# PIC32CX5109BZ31032 register map
Vendor: Microchip Technology; Series: PIC32CXBZ31; File version: 0
CPU: CM4 r0p1, little endian, MPU, FPU, 3 interrupt priority bits, 43 interrupts
Registers are 32-bit, read-write, reset 0x0 unless marked. A register's access mark holds for its fields unless they carry their own. Offsets are from the block's base; [hi:lo] are bit positions.

## ROT — Secure Root of Trust Macro
Base 0x44002C00
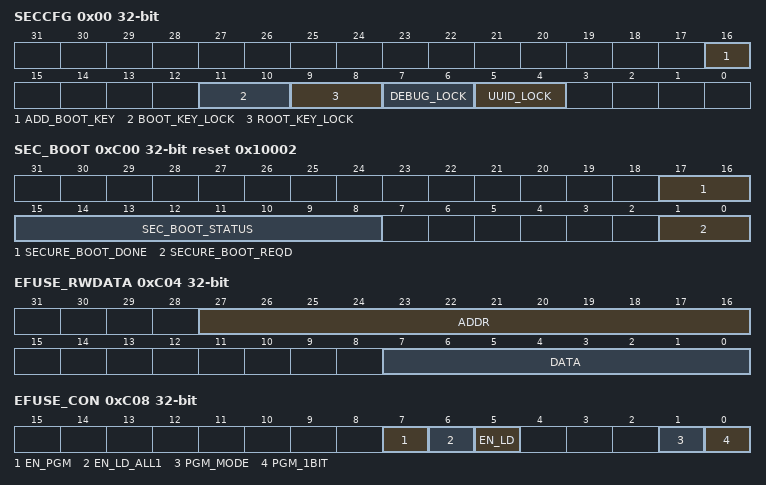
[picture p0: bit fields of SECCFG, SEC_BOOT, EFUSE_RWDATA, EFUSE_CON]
0x00 SECCFG — Secure Configuration HOLDING REGISTER1,2
  [16] ADD_BOOT_KEY — Additional boot Key bit
  [11:10] BOOT_KEY_LOCK — Lock bits for Secure Boot/OTA Key
    0=BOOT_KEY_NOT_LCK_0 (Secure boot key is not locked); 1=BOOT_KEY_LCK_1 (Secure boot key is locked and cannot be programmed); 2=BOOT_KEY_LCK_2 (Secure boot key is locked and cannot be programmed); 3=BOOT_KEY_LCK_3 (Secure boot key is locked and cannot be programmed)
  [9:8] ROOT_KEY_LOCK — Lock bits for storage root Key
    0=ROOT_KEY_NOT_LCK_0 (Storage root key is not locked); 1=ROOT_KEY_LCK_1 (Storage root key is locked and cannot be programmed); 2=ROOT_KEY_LCK_2 (Storage root key is locked and cannot be programmed); 3=ROOT_KEY_LCK_3 (Storage root key is locked and cannot be programmed)
  [7:6] DEBUG_LOCK — Lock bits for debug/programming
    0=DEBUG_NOT_LCK_0 (Debug is not locked); 1=DEBUG_LCK_1 (Debug is locked); 2=DEBUG_LCK_2 (Debug is locked); 3=DEBUG_LCK_3 (Debug is locked)
  [5:4] UUID_LOCK — Programming lock bits for Unique ID fuses
    0=UUID_NOT_LCK_0 (Unique ID is not locked); 1=UUID_LCK_1 (Unique ID is locked and cannot be programmed); 2=UUID_LCK_2 (Unique ID is locked and cannot be programmed); 3=UUID_LCK_3 (Unique ID is locked and cannot be programmed)
0xC00 SEC_BOOT reset 0x10002 — Secure Boot Register
  [17:16] SECURE_BOOT_DONE — Bits to indicate that secure boot is done
    0=SEC_BOOT_DONE_0 (S ecure boot is done); 1=SEC_BOOT_NOT_DONE_1 (S ecure boot is not done); 2=SEC_BOOT_NOT_DONE_2 (S ecure boot is not done); 3=SEC_BOOT_DONE_3 (S ecure boot is done)
  [15:8] SEC_BOOT_STATUS — Bits to indicate that secure boot status
  [1:0] SECURE_BOOT_REQD — Bits to indicate that secure boot is required on the next device reset.
    0=SEC_BOOT_REQD_0 (Secure boot code authentication is required); 1=SEC_BOOT_NOT_REQD_1 (Secure boot code authentication is NOT required); 2=SEC_BOOT_NOT_REQD_2 (Secure boot code authentication is NOT required); 3=SEC_BOOT_REQD_3 (Secure boot code authentication is required)
0xC04 EFUSE_RWDATA
  [27:16] ADDR — eFuse Program/Read Address
  [7:0] DATA — eFuse Program (Write) Data
0xC08 EFUSE_CON — Efuse Configuration Register2
  [7] EN_PGM — eFuse Programming Start bit
    0=EN_PGM_COMPLETED (EFuse Programming operation has completed); 1=EN_PGM_START (Start eFuse Programming operation)
  [6] EN_LD_ALL1 — eFuse Panel Read Start bit for loading into the holding registers
    0=ENLD_ALL1_READ_COMPLETED (EFuse Read operation has completed); 1=ENLD_ALL1_READ_START (Start eFuse Read operation for entire eFuse panel)
  [5] EN_LD — eFuse Word Read Start bit for loading the fuse byte pointed by ADDR field into the holding register
    0=ENLD_READ_COMPLETED (EFuse Read operation has completed); 1=ENLD_READ_START (Start eFuse Read operation for specified eFuse word as addressed in EFUSE_RWDATA register)
  [1] PGM_MODE — eFuse Programming Mode Enable bit
    0=PGM_MODE_DISABLED (EFuse Programming disabled); 1=PGM_MODE_ENABLED (EFuse Programming enabled)
  [0] PGM_1BIT — eFuse CTRL to program 1 bit at a time. Valid only when EN_PGM is set
    0=EFUSE_RW_15_0 (EFuse controller will program EFUSE_RWDATA.DATA[15:0] to the address in EFUSE_RWDATA.ADDR[11:3]); 1=EFUSE_RW_0 (EFuse controller will program EFUSE_RWDATA.DATA[0] to the address in EFUSE_RWDATA.ADDR[11:0])

## SysTick — System timer
Base 0xE000E010
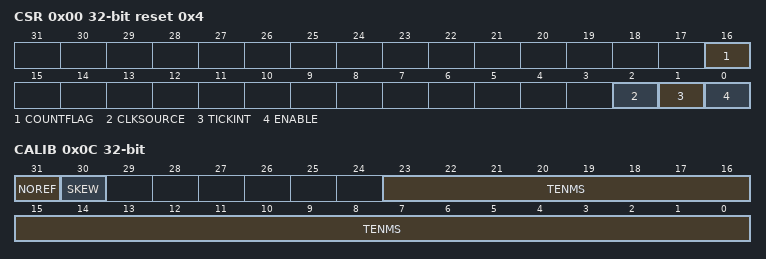
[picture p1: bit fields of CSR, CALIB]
0x00 CSR reset 0x4 — SysTick Control and Status Register
  [16] COUNTFLAG — Timer counted to 0 since last read of register
  [2] CLKSOURCE — Clock Source 0=external, 1=processor
    0=External clock; 1=Processor clock
  [1] TICKINT — SysTick Exception Request Enable
    0=Counting down to 0 does not assert the SysTick exception request; 1=Counting down to 0 asserts the SysTick exception request
  [0] ENABLE — SysTick Counter Enable
    0=Counter disabled; 1=Counter enabled
0x04 RVR — SysTick Reload Value Register
  [23:0] RELOAD — Value to load into the SysTick Current Value Register when the counter reaches 0
0x08 CVR — SysTick Current Value Register
  [23:0] CURRENT — Current value at the time the register is accessed
0x0C CALIB ro — SysTick Calibration Value Register
  [31] NOREF — No Separate Reference Clock
    0=The reference clock is provided; 1=The reference clock is not provided
  [30] SKEW — TENMS is rounded from non-integer ratio
    0=10ms calibration value is exact; 1=10ms calibration value is inexact, because of the clock frequency
  [23:0] TENMS — Reload value to use for 10ms timing

## TPI — Trace Port Interface Register
Base 0xE0040000
0x00 SSPSR ro — Supported Parallel Port Size Register
0x04 CSPSR — Current Parallel Port Size Register
0x10 ACPR — Asynchronous Clock Prescaler Register
  [12:0] PRESCALER
0xF0 SPPR — Selected Pin Protocol Register
  [1:0] TXMODE
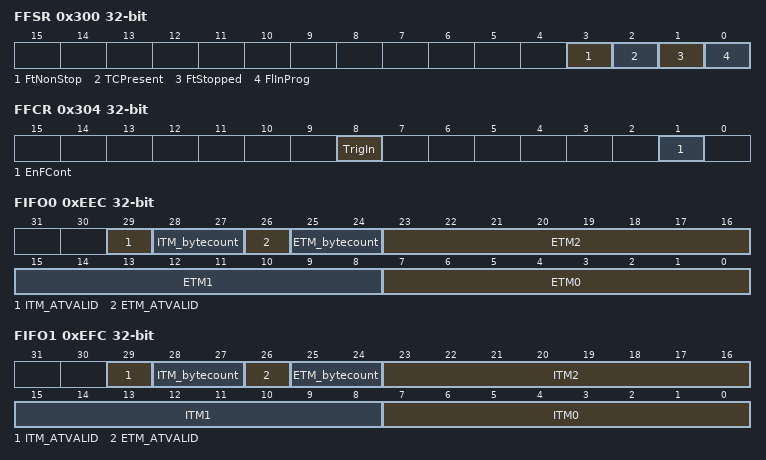
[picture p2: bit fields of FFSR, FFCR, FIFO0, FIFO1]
0x300 FFSR ro — Formatter and Flush Status Register
  [3] FtNonStop, [2] TCPresent, [1] FtStopped, [0] FlInProg
0x304 FFCR — Formatter and Flush Control Register
  [8] TrigIn, [1] EnFCont
0x308 FSCR ro — Formatter Synchronization Counter Register
0xEE8 TRIGGER ro
  [0] TRIGGER
0xEEC FIFO0 ro — Integration ETM Data
  [29] ITM_ATVALID, [28:27] ITM_bytecount, [26] ETM_ATVALID, [25:24] ETM_bytecount, [23:16] ETM2, [15:8] ETM1, [7:0] ETM0
0xEF0 ITATBCTR2 ro
  [0] ATREADY
0xEF8 ITATBCTR0 ro
  [0] ATREADY
0xEFC FIFO1 ro — Integration ITM Data
  [29] ITM_ATVALID, [28:27] ITM_bytecount, [26] ETM_ATVALID, [25:24] ETM_bytecount, [23:16] ITM2, [15:8] ITM1, [7:0] ITM0
0xF00 ITCTRL — Integration Mode Control
  [0] Mode
0xFA0 CLAIMSET — Claim tag set
0xFA4 CLAIMCLR — Claim tag clear
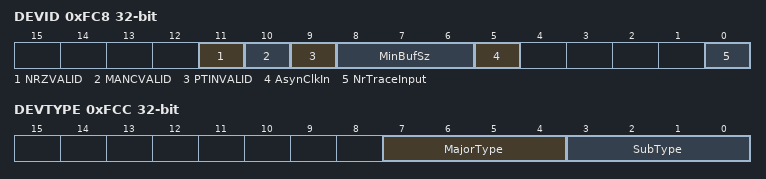
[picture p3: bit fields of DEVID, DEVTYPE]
0xFC8 DEVID ro — TPIU_DEVID
  [11] NRZVALID, [10] MANCVALID, [9] PTINVALID, [8:6] MinBufSz, [5] AsynClkIn, [0] NrTraceInput
0xFCC DEVTYPE ro — TPIU_DEVTYPE
  [7:4] MajorType, [3:0] SubType

## WDT — Watch Dog Timer
Base 0x44000500
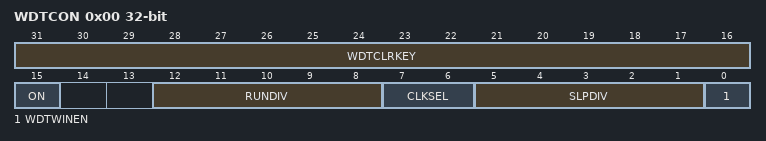
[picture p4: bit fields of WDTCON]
0x00 WDTCON — Watchdog Timer Control Register
  [31:16] WDTCLRKEY
  [15] ON — Watchdog Timer Enable bit
    1=WDTEN (The WDT module is enabled); 0=WDTOFF (The WDT module is disabled)
  [12:8] RUNDIV
  [7:6] CLKSEL
  [5:1] SLPDIV
  [0] WDTWINEN — Watchdog Timer Window Enable bit
    1=WDTWINEN (Enable windowed Watchdog Timer); 0=WDTWINDIS (Disable windowed Watchdog Timer)
0x04 WDTCONCLR
0x08 WDTCONSET
0x0C WDTCONINV
